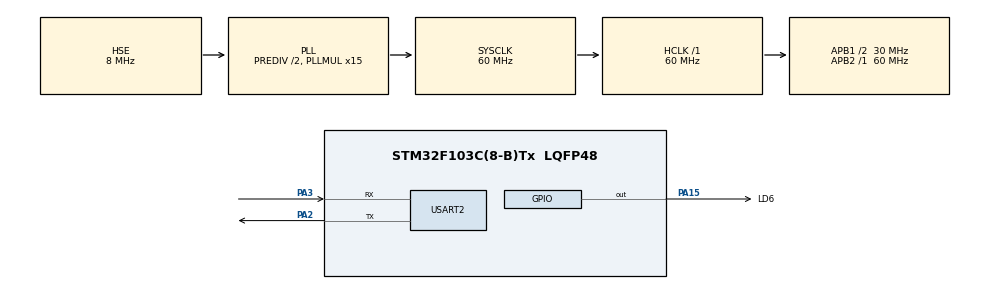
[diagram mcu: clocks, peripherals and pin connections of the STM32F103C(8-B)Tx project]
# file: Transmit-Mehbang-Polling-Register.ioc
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Dma.Request0=USART2_RX
Dma.Request1=USART2_TX
Dma.USART2_RX.0.Direction=DMA_PERIPH_TO_MEMORY
Dma.USART2_RX.0.Instance=DMA1_Channel6
Dma.USART2_RX.0.MemDataAlignment=DMA_MDATAALIGN_BYTE
Dma.USART2_RX.0.MemInc=DMA_MINC_ENABLE
Dma.USART2_RX.0.Mode=DMA_CIRCULAR
Dma.USART2_RX.0.PeriphDataAlignment=DMA_PDATAALIGN_BYTE
Dma.USART2_RX.0.PeriphInc=DMA_PINC_DISABLE
Dma.USART2_RX.0.Priority=DMA_PRIORITY_LOW
Dma.USART2_TX.1.Direction=DMA_MEMORY_TO_PERIPH
Dma.USART2_TX.1.Instance=DMA1_Channel7
Dma.USART2_TX.1.MemDataAlignment=DMA_MDATAALIGN_BYTE
Dma.USART2_TX.1.MemInc=DMA_MINC_ENABLE
Dma.USART2_TX.1.Mode=DMA_NORMAL
Dma.USART2_TX.1.PeriphDataAlignment=DMA_PDATAALIGN_BYTE
Dma.USART2_TX.1.PeriphInc=DMA_PINC_DISABLE
Dma.USART2_TX.1.Priority=DMA_PRIORITY_LOW
Mcu.Family=STM32F1
Mcu.Name=STM32F103C(8-B)Tx
Mcu.Package=LQFP48
NVIC.DMA1_Channel6_IRQn=true\:0\:0\:false\:false\:true\:false\:true\:true
NVIC.DMA1_Channel7_IRQn=true\:0\:0\:false\:false\:true\:false\:true\:true
NVIC.PriorityGroup=NVIC_PRIORITYGROUP_4
NVIC.TIM2_IRQn=true\:0\:0\:false\:false\:true\:true\:true\:true
NVIC.USART2_IRQn=true\:0\:0\:false\:false\:true\:false\:true\:true
PA13.Mode=Serial_Wire
PA13.Signal=SYS_JTMS-SWDIO
PA14.Mode=Serial_Wire
PA14.Signal=SYS_JTCK-SWCLK
PA15.GPIO_Label=LD6
PA15.Signal=GPIO_Output
PA2.Mode=Asynchronous
PA2.Signal=USART2_TX
PA3.Mode=Asynchronous
PA3.Signal=USART2_RX
PD0-OSC_IN.Mode=HSE-External-Oscillator
PD0-OSC_IN.Signal=RCC_OSC_IN
PD1-OSC_OUT.Mode=HSE-External-Oscillator
PD1-OSC_OUT.Signal=RCC_OSC_OUT
ProjectManager.HeapSize=0x200
ProjectManager.StackSize=0x400
ProjectManager.TargetToolchain=MDK-ARM V5.32
RCC.AHBFreq_Value=60000000
RCC.APB1CLKDivider=RCC_HCLK_DIV2
RCC.APB1Freq_Value=30000000
RCC.APB1TimFreq_Value=60000000
RCC.APB2Freq_Value=60000000
RCC.APB2TimFreq_Value=60000000
RCC.HCLKFreq_Value=60000000
RCC.HSEDivPLL=RCC_HSE_PREDIV_DIV2
RCC.PLLMUL=RCC_PLL_MUL15
RCC.PLLSourceVirtual=RCC_PLLSOURCE_HSE
RCC.SYSCLKFreq_VALUE=60000000
RCC.SYSCLKSource=RCC_SYSCLKSOURCE_PLLCLK
RCC.USBFreq_Value=60000000
TIM2.Period=3200-1
TIM2.Prescaler=60-1
TIM2.TIM_MasterOutputTrigger=TIM_TRGO_UPDATE
USART2.Parity=PARITY_ODD
USART2.VirtualMode=VM_ASYNC
USART2.WordLength=WORDLENGTH_9B
VP_TIM2_VS_ClockSourceINT.Mode=Internal
board=custom

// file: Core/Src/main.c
/* USER CODE BEGIN Header */
/**
  ******************************************************************************
  * @file           : main.c
  * @brief          : Main program body
  ******************************************************************************
  * @attention
  *
  * Copyright (c) 2024 STMicroelectronics.
  * All rights reserved.
  *
  * This software is licensed under terms that can be found in the LICENSE file
  * in the root directory of this software component.
  * If no LICENSE file comes with this software, it is provided AS-IS.
  *
  ******************************************************************************
  */
/* USER CODE END Header */
#include "main.h"
#include "dma.h"
#include "tim.h"
#include "usart.h"
#include "gpio.h"

/* USER CODE BEGIN PV */
uint16_t mehsize = 7;
uint8_t txIndex =0 ;
/* USER CODE END PV */

void SystemClock_Config(void);

int main(void)
{

  /* MCU Configuration--------------------------------------------------------*/

  /* Reset of all peripherals, Initializes the Flash interface and the Systick. */
  HAL_Init();

  /* Configure the system clock */
  SystemClock_Config();

  /* Initialize all configured peripherals */
  MX_GPIO_Init();
  MX_DMA_Init();
  MX_TIM2_Init();
  MX_USART2_UART_Init();
  /* USER CODE BEGIN 2 */
	HAL_TIM_Base_Start_IT(&htim2);
	USART2->CR1 |= USART_CR1_TE;
  /* USER CODE END 2 */

  /* Infinite loop */
  while (1)
  {

  }
}

void SystemClock_Config(void)
{
  RCC_OscInitTypeDef RCC_OscInitStruct = {0};
  RCC_ClkInitTypeDef RCC_ClkInitStruct = {0};

  /** Initializes the RCC Oscillators according to the specified parameters
  * in the RCC_OscInitTypeDef structure.
  */
  RCC_OscInitStruct.OscillatorType = RCC_OSCILLATORTYPE_HSE;
  RCC_OscInitStruct.HSEState = RCC_HSE_ON;
  RCC_OscInitStruct.HSEPredivValue = RCC_HSE_PREDIV_DIV2;
  RCC_OscInitStruct.HSIState = RCC_HSI_ON;
  RCC_OscInitStruct.PLL.PLLState = RCC_PLL_ON;
  RCC_OscInitStruct.PLL.PLLSource = RCC_PLLSOURCE_HSE;
  RCC_OscInitStruct.PLL.PLLMUL = RCC_PLL_MUL15;
  if (HAL_RCC_OscConfig(&RCC_OscInitStruct) != HAL_OK)
  {
    Error_Handler();
  }

  /** Initializes the CPU, AHB and APB buses clocks
  */
  RCC_ClkInitStruct.ClockType = RCC_CLOCKTYPE_HCLK|RCC_CLOCKTYPE_SYSCLK
                              |RCC_CLOCKTYPE_PCLK1|RCC_CLOCKTYPE_PCLK2;
  RCC_ClkInitStruct.SYSCLKSource = RCC_SYSCLKSOURCE_PLLCLK;
  RCC_ClkInitStruct.AHBCLKDivider = RCC_SYSCLK_DIV1;
  RCC_ClkInitStruct.APB1CLKDivider = RCC_HCLK_DIV2;
  RCC_ClkInitStruct.APB2CLKDivider = RCC_HCLK_DIV1;

  if (HAL_RCC_ClockConfig(&RCC_ClkInitStruct, FLASH_LATENCY_2) != HAL_OK)
  {
    Error_Handler();
  }
}

/* USER CODE BEGIN 4 */

void transmit (char *character){
	while(*character){

		while (!(USART2->SR & USART_SR_TXE));

		USART2->DR = *character++;

		while (!(USART2->SR & (1<<6)));

	}
}

void HAL_TIM_PeriodElapsedCallback(TIM_HandleTypeDef *htim){
	transmit("Mehbang");
}
/* USER CODE END 4 */

void Error_Handler(void)
{
  __disable_irq();
  while (1)
  {
  }
}
